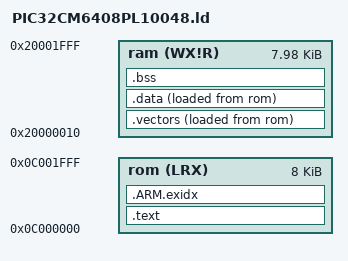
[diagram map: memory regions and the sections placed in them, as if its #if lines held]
/*--------------------------------------------------------------------------
 * MPLAB XC32 Compiler -  PIC32CM6408PL10048 linker script
 * 
 * Copyright (c) 2025 Microchip Technology Inc. and its subsidiaries.
 *
 * Licensed under the Apache License, Version 2.0 (the "License");
 * you may not use this file except in compliance with the License.
 * You may obtain a copy of the License at
 *
 *   http://www.apache.org/licenses/LICENSE-2.0
 *
 * Unless required by applicable law or agreed to in writing, software
 * distributed under the License is distributed on an "AS IS" BASIS,
 * WITHOUT WARRANTIES OR CONDITIONS OF ANY KIND, either express or implied.
 * See the License for the specific language governing permissions and
 * limitations under the License.
 *
 */
OUTPUT_FORMAT("elf32-littlearm", "elf32-littlearm", "elf32-littlearm")
OUTPUT_ARCH(arm)
SEARCH_DIR(.)

/*
 *  Define the __XC32_RESET_HANDLER_NAME macro on the command line when you
 *  want to use a different name for the Reset Handler function.
 */
#ifndef __XC32_RESET_HANDLER_NAME
#define __XC32_RESET_HANDLER_NAME Reset_Handler
#endif /* __XC32_RESET_HANDLER_NAME */

/*  Set the entry point in the ELF file. Once the entry point is in the ELF
 *  file, you can then use the --write-sla option to xc32-bin2hex to place
 *  the address into the hex file using the SLA field (RECTYPE 5). This hex
 *  record may be useful for a bootloader that needs to determine the entry
 *  point to the application.
 */
ENTRY(__XC32_RESET_HANDLER_NAME)

/*************************************************************************
 * Memory-Region Macro Definitions
 * The XC32 linker preprocesses linker scripts. You may define these
 * macros in the MPLAB X project properties or on the command line when
 * calling the linker via the xc32-gcc shell.
 *************************************************************************/

#  define ROM_ORIGIN 0xc000000

#  define ROM_LENGTH 0x2000
#if (ROM_LENGTH > 0x10000)
#  error ROM_LENGTH is greater than the max size of 0x10000
#endif


#  define RAM_ORIGIN (0x20000000+16)


#  define RAM_LENGTH (0x2000-16)
#if (RAM_LENGTH > 0x2000)
#  error RAM_LENGTH is greater than the max size of 0x2000
#endif

/*************************************************************************
 * Memory-Region Definitions
 * The MEMORY command describes the location and size of blocks of memory
 * on the target device. The command below uses the macros defined above.
 *************************************************************************/
MEMORY
{
  rom (LRX) : ORIGIN = ROM_ORIGIN, LENGTH = ROM_LENGTH
  ram (WX!R) : ORIGIN = RAM_ORIGIN, LENGTH = RAM_LENGTH

}

/*************************************************************************
 * Section Definitions - Map input sections to output sections
 *************************************************************************/
SECTIONS
{

    /*
     * The linker moves the .vectors section into itcm when itcm is
     * enabled via the -mitcm option, but only when this .vectors output
     * section exists in the linker script.
     */
    .vectors :
    {
        . = ALIGN(4);
        KEEP(*(.vectors .vectors.*))
        _sfixed = .;
    } > ram AT > rom

    .text :
    {
        . = ALIGN(4);
        *(.glue_7t) *(.glue_7)
        *(.gnu.linkonce.r.*)
        *(.ARM.extab* .gnu.linkonce.armextab.*)

        . = ALIGN(4);

        /* allow for .romfunc section to keep individual functions in flash */
        *(.romfunc)
        *(.romfunc.*)

        . = ALIGN(4);
        _efixed = .;            /* End of text section */
    } > rom

    /* .ARM.exidx is sorted, so has to go in its own output section.  */
    PROVIDE_HIDDEN (__exidx_start = .);
    .ARM.exidx :
    {
      *(.ARM.exidx* .gnu.linkonce.armexidx.*)
    } > rom
    PROVIDE_HIDDEN (__exidx_end = .);

    . = ALIGN(4);
    _etext = .;

    /* Locate text/rodata in special data section to be copied
       in startup sequence. */
    .data :
    {
        . = ALIGN(4);
        __data_start__ = .;
        _sdata = .;
        *(.dinit)
        *(.text)
        *(.text.*)
        *(.rodata)
        *(.rodata.*)
        . = ALIGN(4);
        __data_end__ = .;
        _edata = .;
    } > ram AT > rom

    /*
     *  Align here to ensure that the .bss section occupies space up to
     *  _end.  Align after .bss to ensure correct alignment even if the
     *  .bss section disappears because there are no input sections.
     *
     *  Note that input sections named .bss* are no longer mapped here.
     *  The best-fit allocator locates them, so that they may flow
     *  around absolute sections as needed.
     */
    .bss (NOLOAD) :
    {
        . = ALIGN(4);
        __bss_start__ = .;
        _sbss = . ;
        _szero = .;
        *(COMMON)
        *(.bss)
        *(.bss.*)
        . = ALIGN(4);
        __bss_end__ = .;
        _ebss = . ;
        _ezero = .;
    } > ram AT > ram

    . = ALIGN(4);
    _end = . ;
    _ram_end_ = ORIGIN(ram) + LENGTH(ram) -1 ;
    
}
